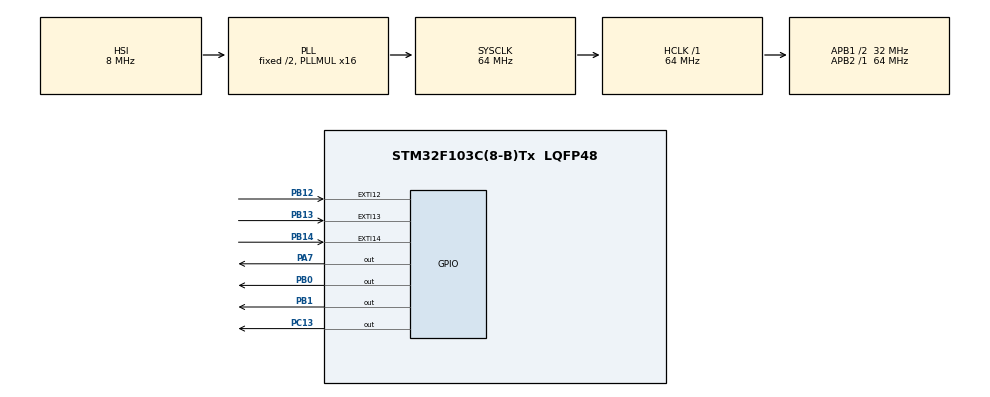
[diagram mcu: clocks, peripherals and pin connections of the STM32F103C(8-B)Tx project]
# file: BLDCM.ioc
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Mcu.Family=STM32F1
Mcu.Name=STM32F103C(8-B)Tx
Mcu.Package=LQFP48
NVIC.EXTI15_10_IRQn=true\:0\:0\:false\:false\:true\:true\:true
NVIC.PriorityGroup=NVIC_PRIORITYGROUP_4
PA13.Mode=Serial_Wire
PA13.Signal=SYS_JTMS-SWDIO
PA14.Mode=Serial_Wire
PA14.Signal=SYS_JTCK-SWCLK
PA6.Signal=S_TIM3_CH1
PA7.Signal=GPIO_Output
PB0.Signal=GPIO_Output
PB1.Signal=GPIO_Output
PB12.GPIO_ModeDefaultEXTI=GPIO_MODE_IT_RISING_FALLING
PB12.GPIO_PuPd=GPIO_PULLDOWN
PB12.Signal=GPXTI12
PB13.GPIO_ModeDefaultEXTI=GPIO_MODE_IT_RISING_FALLING
PB13.GPIO_PuPd=GPIO_PULLDOWN
PB13.Signal=GPXTI13
PB14.GPIO_ModeDefaultEXTI=GPIO_MODE_IT_RISING_FALLING
PB14.GPIO_PuPd=GPIO_PULLDOWN
PB14.Signal=GPXTI14
PB6.Signal=S_TIM4_CH1
PB7.Signal=S_TIM4_CH2
PC13-TAMPER-RTC.Signal=GPIO_Output
PC14-OSC32_IN.Mode=LSE-External-Oscillator
PC14-OSC32_IN.Signal=RCC_OSC32_IN
PC15-OSC32_OUT.Mode=LSE-External-Oscillator
PC15-OSC32_OUT.Signal=RCC_OSC32_OUT
ProjectManager.HeapSize=0x200
ProjectManager.StackSize=0x400
ProjectManager.TargetToolchain=STM32CubeIDE
RCC.AHBFreq_Value=64000000
RCC.APB1CLKDivider=RCC_HCLK_DIV2
RCC.APB1Freq_Value=32000000
RCC.APB1TimFreq_Value=64000000
RCC.APB2Freq_Value=64000000
RCC.APB2TimFreq_Value=64000000
RCC.HCLKFreq_Value=64000000
RCC.PLLMUL=RCC_PLL_MUL16
RCC.SYSCLKFreq_VALUE=64000000
RCC.SYSCLKSource=RCC_SYSCLKSOURCE_PLLCLK
RCC.USBFreq_Value=64000000
SH.S_TIM3_CH1.0=TIM3_CH1
SH.S_TIM4_CH1.0=TIM4_CH1
SH.S_TIM4_CH2.0=TIM4_CH2
board=custom

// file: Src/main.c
/* USER CODE BEGIN Header */
/**
  ******************************************************************************
  * @file           : main.c
  * @brief          : Main program body
  ******************************************************************************
  * @attention
  *
  * <h2><center>&copy; Copyright (c) 2019 STMicroelectronics.
  * All rights reserved.</center></h2>
  *
  * This software component is licensed by ST under BSD 3-Clause license,
  * the "License"; You may not use this file except in compliance with the
  * License. You may obtain a copy of the License at:
  *                        opensource.org/licenses/BSD-3-Clause
  *
  ******************************************************************************
  */
/* USER CODE END Header */

#include "main.h"

void SystemClock_Config(void);
static void MX_GPIO_Init(void);

int main(void)
{

  /* MCU Configuration--------------------------------------------------------*/

  /* Reset of all peripherals, Initializes the Flash interface and the Systick. */
  HAL_Init();

  /* Configure the system clock */
  SystemClock_Config();

  /* Initialize all configured peripherals */
  MX_GPIO_Init();
  /* USER CODE BEGIN 2 */
  //HAL_GPIO_EXTI_IRQHandler(GPIO_PIN_12);
  main_cpp();
  /* USER CODE END 2 */

  /* Infinite loop */
  while (1)
  {

  }
}

void SystemClock_Config(void)
{
  RCC_OscInitTypeDef RCC_OscInitStruct = {0};
  RCC_ClkInitTypeDef RCC_ClkInitStruct = {0};

  /** Initializes the CPU, AHB and APB busses clocks
  */
  RCC_OscInitStruct.OscillatorType = RCC_OSCILLATORTYPE_HSI;
  RCC_OscInitStruct.HSIState = RCC_HSI_ON;
  RCC_OscInitStruct.HSICalibrationValue = RCC_HSICALIBRATION_DEFAULT;
  RCC_OscInitStruct.PLL.PLLState = RCC_PLL_ON;
  RCC_OscInitStruct.PLL.PLLSource = RCC_PLLSOURCE_HSI_DIV2;
  RCC_OscInitStruct.PLL.PLLMUL = RCC_PLL_MUL16;
  if (HAL_RCC_OscConfig(&RCC_OscInitStruct) != HAL_OK)
  {
    Error_Handler();
  }
  /** Initializes the CPU, AHB and APB busses clocks
  */
  RCC_ClkInitStruct.ClockType = RCC_CLOCKTYPE_HCLK|RCC_CLOCKTYPE_SYSCLK
                              |RCC_CLOCKTYPE_PCLK1|RCC_CLOCKTYPE_PCLK2;
  RCC_ClkInitStruct.SYSCLKSource = RCC_SYSCLKSOURCE_PLLCLK;
  RCC_ClkInitStruct.AHBCLKDivider = RCC_SYSCLK_DIV1;
  RCC_ClkInitStruct.APB1CLKDivider = RCC_HCLK_DIV2;
  RCC_ClkInitStruct.APB2CLKDivider = RCC_HCLK_DIV1;

  if (HAL_RCC_ClockConfig(&RCC_ClkInitStruct, FLASH_LATENCY_2) != HAL_OK)
  {
    Error_Handler();
  }
}

static void MX_GPIO_Init(void)
{
  GPIO_InitTypeDef GPIO_InitStruct = {0};

  /* GPIO Ports Clock Enable */
  __HAL_RCC_GPIOC_CLK_ENABLE();
  __HAL_RCC_GPIOA_CLK_ENABLE();
  __HAL_RCC_GPIOB_CLK_ENABLE();

  /*Configure GPIO pin Output Level */
  HAL_GPIO_WritePin(GPIOC, GPIO_PIN_13, GPIO_PIN_RESET);

  /*Configure GPIO pin Output Level */
  HAL_GPIO_WritePin(GPIOA, GPIO_PIN_7, GPIO_PIN_RESET);

  /*Configure GPIO pin Output Level */
  HAL_GPIO_WritePin(GPIOB, GPIO_PIN_0|GPIO_PIN_1, GPIO_PIN_RESET);

  /*Configure GPIO pin : PC13 */
  GPIO_InitStruct.Pin = GPIO_PIN_13;
  GPIO_InitStruct.Mode = GPIO_MODE_OUTPUT_PP;
  GPIO_InitStruct.Pull = GPIO_NOPULL;
  GPIO_InitStruct.Speed = GPIO_SPEED_FREQ_LOW;
  HAL_GPIO_Init(GPIOC, &GPIO_InitStruct);

  /*Configure GPIO pin : PA6 */
  GPIO_InitStruct.Pin = GPIO_PIN_6;
  GPIO_InitStruct.Mode = GPIO_MODE_AF_PP;
  GPIO_InitStruct.Speed = GPIO_SPEED_FREQ_LOW;
  HAL_GPIO_Init(GPIOA, &GPIO_InitStruct);

  /*Configure GPIO pin : PA7 */
  GPIO_InitStruct.Pin = GPIO_PIN_7;
  GPIO_InitStruct.Mode = GPIO_MODE_OUTPUT_PP;
  GPIO_InitStruct.Pull = GPIO_NOPULL;
  GPIO_InitStruct.Speed = GPIO_SPEED_FREQ_LOW;
  HAL_GPIO_Init(GPIOA, &GPIO_InitStruct);

  /*Configure GPIO pins : PB0 PB1 */
  GPIO_InitStruct.Pin = GPIO_PIN_0|GPIO_PIN_1;
  GPIO_InitStruct.Mode = GPIO_MODE_OUTPUT_PP;
  GPIO_InitStruct.Pull = GPIO_NOPULL;
  GPIO_InitStruct.Speed = GPIO_SPEED_FREQ_LOW;
  HAL_GPIO_Init(GPIOB, &GPIO_InitStruct);

  /*Configure GPIO pins : PB12 PB13 PB14 */
  GPIO_InitStruct.Pin = GPIO_PIN_12|GPIO_PIN_13|GPIO_PIN_14;
  GPIO_InitStruct.Mode = GPIO_MODE_IT_RISING_FALLING;
  GPIO_InitStruct.Pull = GPIO_PULLDOWN;
  HAL_GPIO_Init(GPIOB, &GPIO_InitStruct);

  /*Configure GPIO pins : PB6 PB7 */
  GPIO_InitStruct.Pin = GPIO_PIN_6|GPIO_PIN_7;
  GPIO_InitStruct.Mode = GPIO_MODE_AF_PP;
  GPIO_InitStruct.Speed = GPIO_SPEED_FREQ_LOW;
  HAL_GPIO_Init(GPIOB, &GPIO_InitStruct);

  /* EXTI interrupt init*/
  HAL_NVIC_SetPriority(EXTI15_10_IRQn, 0, 0);
  HAL_NVIC_EnableIRQ(EXTI15_10_IRQn);

}

void Error_Handler(void)
{
}

/************************ (C) COPYRIGHT STMicroelectronics *****END OF FILE****/
